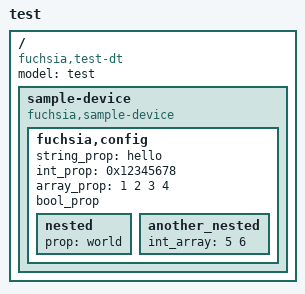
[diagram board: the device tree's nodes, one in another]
// Copyright 2026 The Fuchsia Authors. All rights reserved.
// Use of this source code is governed by a BSD-style license that can be
// found in the LICENSE file.
/dts-v1/;

/ {
	compatible = "fuchsia,test-dt";
	model = "test";
	#address-cells = <2>;
	#size-cells = <2>;

	/* Add test nodes here */
	sample-device {
		compatible = "fuchsia,sample-device";

		fuchsia,config {
			string_prop = "hello";
			int_prop = <0x12345678>;
			array_prop = <1 2 3 4>;
			bool_prop;

			nested {
				prop = "world";
			};

			another_nested {
				int_array = <5 6>;
			};
		};
	};
};
